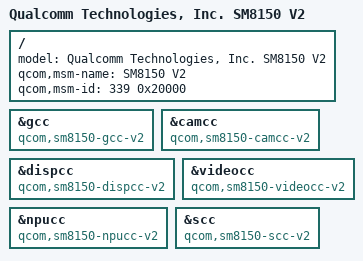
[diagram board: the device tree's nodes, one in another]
#include "sm8150.dtsi"

/ {
	model = "Qualcomm Technologies, Inc. SM8150 V2";
	qcom,msm-name = "SM8150 V2";
	qcom,msm-id = <339 0x20000>;
};

/* Remove smmu nodes specific to SM8150 */
/delete-node/ &apps_smmu;
/delete-node/ &kgsl_smmu;

&gcc {
	compatible = "qcom,sm8150-gcc-v2", "syscon";
};

&camcc {
	compatible = "qcom,sm8150-camcc-v2", "syscon";
};

&dispcc {
	compatible = "qcom,sm8150-dispcc-v2", "syscon";
};

&videocc {
	compatible = "qcom,sm8150-videocc-v2", "syscon";
};

&npucc {
	compatible = "qcom,sm8150-npucc-v2", "syscon";
};

&scc {
	compatible = "qcom,sm8150-scc-v2", "syscon";
};

#include "msm-arm-smmu-sm8150-v2.dtsi"
